# BAT32G157 register map
Vendor: Cmsemicon; Series: BAT32G157; File version: 1.0
CPU: CM0+ r0p1, little endian, no MPU, no FPU, VTOR, 2 interrupt priority bits
Registers are 8-bit, read-write, reset 0x0 unless marked. A register's access mark holds for its fields unless they carry their own. Offsets are from the block's base; [hi:lo] are bit positions.

## FMC — Flash Memory Controller
Base 0x40020000
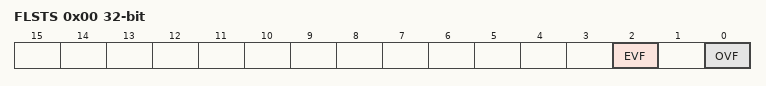
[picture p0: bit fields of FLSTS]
0x00 FLSTS 32-bit — Flash status register
  [2] EVF — Flash hardware verification error flag
  [0] OVF — Flash erase or write operaiton finish
0x04 FLOPMD1 32-bit (reset mask 0xFF) — Flash operation mode register 1
0x08 FLOPMD2 32-bit (reset mask 0xFF) — Flash operation mode register 2
0x0C FLERMD 32-bit (reset mask 0x18) — Flash erase mode register
0x10 FLCERCNT 32-bit (reset mask 0x800001FF) — Flash chip erase control register
0x14 FLSERCNT 32-bit (reset mask 0x800001FF) — Flash sector erase control register
0x18 FLNVSCNT 32-bit (reset mask 0x800001FF) — Flash address setup time (Tnvs) control register
0x1C FLPROCNT 32-bit (reset mask 0x81FF81FF) — Flash program control register
0x20 FLPROT 32-bit (reset mask 0xFF) — Flash protect control register
0x38 FLPRVCNT 32-bit (reset mask 0x800001FF) — Flash program recovery time (Trcv) control register
0x3C FLERVCNT 32-bit (reset mask 0x803FF81FF) — Flash erase recovery time (Trcv) control register

## SAF — Flash memory CRC operation function (High-Speed CRC)
Base 0x40020100
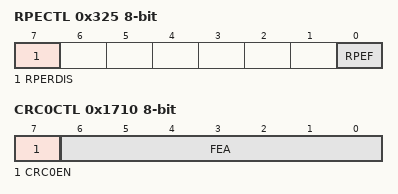
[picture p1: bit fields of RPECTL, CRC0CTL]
0x325 RPECTL — RAM parity error control register
  [7] RPERDIS — Disable RAM parity error reset
    0=Enable parity error reset; 1=Disable parity error reset
  [0] RPEF — Parity error status flag
    0=NoError (No parity error has occurred); 1=Error (Parity error has occurred)
0x1710 CRC0CTL — Flash memory CRC control register
  [7] CRC0EN — Control of high-speed CRC operation
  [6:0] FEA — High-speed CRC operation range
0x1712 PGCRCL 16-bit — Flash memory CRC operation result register
0x20378 SFRGD 16-bit (reset mask 0xF) — SFR guard control register
0x231FA CRCD 16-bit (reset mask 0xFF) — CRC data register
0x232AC CRCIN — CRC input register

## QSPI — QSPI communication module
Base 0x64000000
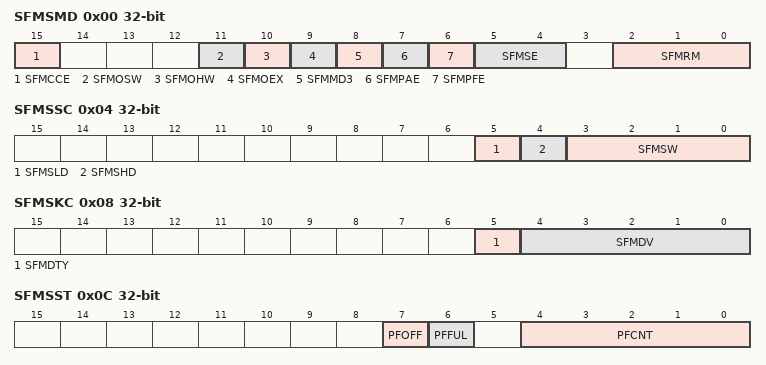
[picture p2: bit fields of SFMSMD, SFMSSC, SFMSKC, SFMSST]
0x00 SFMSMD 32-bit (reset mask 0x1FF7) — Transfer Mode Control Register
  [15] SFMCCE — Read instruction code select
  [11] SFMOSW — Setup time adjustment for serial transmission
  [10] SFMOHW — Hold time adjustment for serial transmission
  [9] SFMOEX — Extension select for the I/O buffer output enable signal for the serial interface
  [8] SFMMD3 — SPI mode select. An initial value is determined by input to CFGMD3
  [7] SFMPAE — Function select for stopping prefetch at locations other than on byte boundaries
  [6] SFMPFE — Prefetch function select
  [5:4] SFMSE — QSSL extension function select after SPI bus access
  [2:0] SFMRM — Serial interface read mode select
0x04 SFMSSC 32-bit (reset mask 0x1F) — Chip Selection Control Register
  [5] SFMSLD — QSSL signal output timing select
  [4] SFMSHD — QSSL signal release timing select
  [3:0] SFMSW — Minimum high-level width select for QSSL signal
0x08 SFMSKC 32-bit — Clock Control Register
  [5] SFMDTY — Duty ratio correction function select for the QSPCLK signal
  [4:0] SFMDV — Serial interface reference cycle select
0x0C SFMSST 32-bit ro — Status Register
  [7] PFOFF — Prefetch function operation state
  [6] PFFUL — Prefetch buffer state
  [4:0] PFCNT — Number of bytes of prefetched data
0x10 SFMCOM 32-bit (reset mask 0xF) — Communication Port Register
  [7:0] SFMD — Port for direct communication with the SPI bus
0x14 SFMCMD 32-bit — Communication Mode Control Register
  [0] DCOM — Mode select for communication with the SPI bus
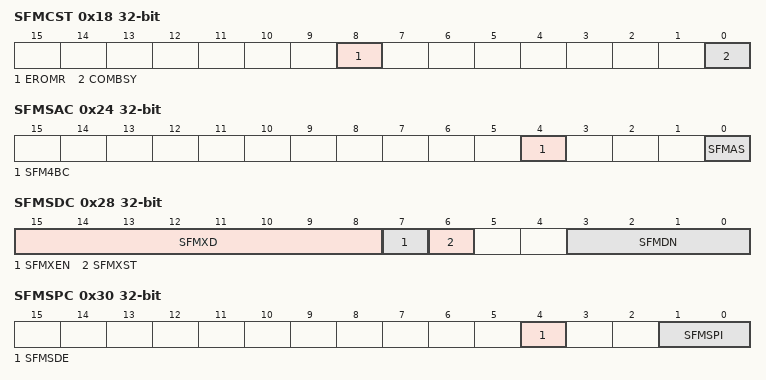
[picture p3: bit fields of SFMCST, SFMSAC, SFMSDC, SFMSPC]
0x18 SFMCST 32-bit (reset mask 0x81) — Communication Status Register
  [8] EROMR — ROM access detection status in direct communication mode
  [0] COMBSY ro — SPI bus cycle completion state in direct communication
0x20 SFMSIC 32-bit (reset mask 0xF) — Instruction Code Register
  [7:0] SFMCIC — Serial flash instruction code to substitute
0x24 SFMSAC 32-bit — Address Mode Control Register
  [4] SFM4BC — Default instruction code select
  [0] SFMAS — Number of address bytes select for the serial interface
0x28 SFMSDC 32-bit — Dummy Cycle Control Register
  [15:8] SFMXD — Mode data for serial flash (control XIP mode)
  [7] SFMXEN — XIP mode permission
  [6] SFMXST ro — XIP mode status
  [3:0] SFMDN — Number of dummy cycles select for Fast Read instructions
0x30 SFMSPC 32-bit — SPI Protocol Control Register
  [4] SFMSDE — Minimum time select for input output switch
  [1:0] SFMSPI — SPI protocol select
0x34 SFMPMD 32-bit — Port Control Register
  [2] SFMWPL — WP pin specification
0x804 SFMCNT1 32-bit — External QSPI Address Register
  [31:26] QSPI_EXT — Bank switching address
